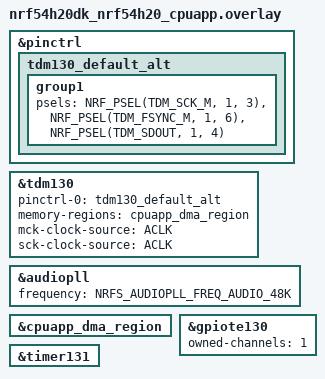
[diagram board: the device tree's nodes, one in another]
/*
 * Copyright (c) 2025 Nordic Semiconductor ASA
 *
 * SPDX-License-Identifier: Apache-2.0
 */

#include "../app.overlay"

&pinctrl {
	tdm130_default_alt: tdm130_default_alt {
		group1 {
			psels = <NRF_PSEL(TDM_SCK_M, 1, 3)>,
				<NRF_PSEL(TDM_FSYNC_M, 1, 6)>,
				<NRF_PSEL(TDM_SDOUT, 1, 4)>;
		};
	};
};

i2s_tx: &tdm130 {
	status = "okay";
	pinctrl-0 = <&tdm130_default_alt>;
	pinctrl-names = "default";
	memory-regions = <&cpuapp_dma_region>;
	mck-clock-source = "ACLK";
	sck-clock-source = "ACLK";
};

&audiopll {
	frequency = <NRFS_AUDIOPLL_FREQ_AUDIO_48K>;
	status = "okay";
};

&cpuapp_dma_region {
	status = "okay";
};

/* PPI channel 1 for GPIOTE used for feedback in edge counter mode */
&gpiote130 {
	status = "okay";
	owned-channels = <1>;
};

&timer131 {
	status = "okay";
};
